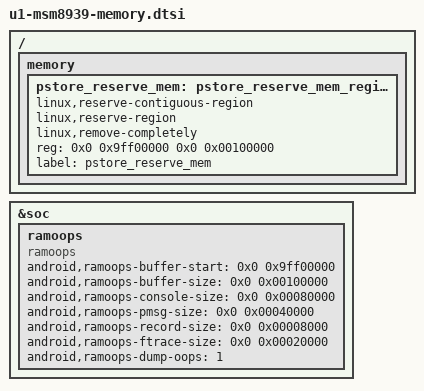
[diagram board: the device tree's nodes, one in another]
/{
	memory {
		pstore_reserve_mem: pstore_reserve_mem_region@0 {
			linux,reserve-contiguous-region;
			linux,reserve-region;
			linux,remove-completely;
			reg = <0x0 0x9ff00000 0x0 0x00100000>;
			label = "pstore_reserve_mem";
		};
	};
};

&soc {
	ramoops {
		compatible = "ramoops";
		status = "ok";

		android,ramoops-buffer-start  = <0x0 0x9ff00000>;
		android,ramoops-buffer-size   = <0x0 0x00100000>;

		android,ramoops-console-size  = <0x0 0x00080000>;
		android,ramoops-pmsg-size     = <0x0 0x00040000>;
		android,ramoops-record-size   = <0x0 0x00008000>;
		android,ramoops-ftrace-size   = <0x0 0x00020000>;

		android,ramoops-dump-oops = <1>;
	};
};
